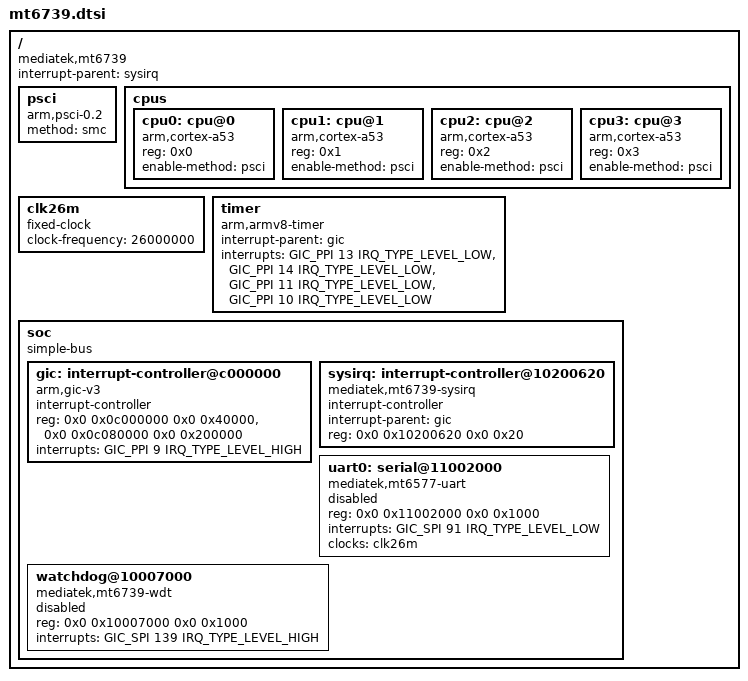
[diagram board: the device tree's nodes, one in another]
// SPDX-License-Identifier: GPL-2.0-only
/*
 * MediaTek MT6739 SoC
 *
 * Minimal mainline-shaped description: CPUs, PSCI, GICv3, arch timer, UART
 * and the top reset controller.  Clock, pinctrl, MMC and display nodes are
 * added as their drivers are ported.
 */

#include <dt-bindings/interrupt-controller/arm-gic.h>
#include <dt-bindings/interrupt-controller/irq.h>

/ {
	compatible = "mediatek,mt6739";
	interrupt-parent = <&sysirq>;
	#address-cells = <2>;
	#size-cells = <2>;

	psci {
		compatible = "arm,psci-0.2";
		method = "smc";
	};

	cpus {
		#address-cells = <1>;
		#size-cells = <0>;

		cpu0: cpu@0 {
			device_type = "cpu";
			compatible = "arm,cortex-a53";
			reg = <0x0>;
			enable-method = "psci";
		};

		cpu1: cpu@1 {
			device_type = "cpu";
			compatible = "arm,cortex-a53";
			reg = <0x1>;
			enable-method = "psci";
		};

		cpu2: cpu@2 {
			device_type = "cpu";
			compatible = "arm,cortex-a53";
			reg = <0x2>;
			enable-method = "psci";
		};

		cpu3: cpu@3 {
			device_type = "cpu";
			compatible = "arm,cortex-a53";
			reg = <0x3>;
			enable-method = "psci";
		};
	};

	clk26m: clk26m {
		compatible = "fixed-clock";
		#clock-cells = <0>;
		clock-frequency = <26000000>;
	};

	timer {
		compatible = "arm,armv8-timer";
		interrupt-parent = <&gic>;
		interrupts = <GIC_PPI 13 IRQ_TYPE_LEVEL_LOW>,
			     <GIC_PPI 14 IRQ_TYPE_LEVEL_LOW>,
			     <GIC_PPI 11 IRQ_TYPE_LEVEL_LOW>,
			     <GIC_PPI 10 IRQ_TYPE_LEVEL_LOW>;
	};

	soc {
		compatible = "simple-bus";
		#address-cells = <2>;
		#size-cells = <2>;
		ranges;

		gic: interrupt-controller@c000000 {
			compatible = "arm,gic-v3";
			#interrupt-cells = <3>;
			#address-cells = <2>;
			#size-cells = <2>;
			interrupt-controller;
			reg = <0x0 0x0c000000 0x0 0x40000>,	/* GICD */
			      <0x0 0x0c080000 0x0 0x200000>;	/* GICR */
			interrupts = <GIC_PPI 9 IRQ_TYPE_LEVEL_HIGH>;
		};

		sysirq: interrupt-controller@10200620 {
			compatible = "mediatek,mt6739-sysirq",
				     "mediatek,mt6577-sysirq";
			interrupt-controller;
			#interrupt-cells = <3>;
			interrupt-parent = <&gic>;
			reg = <0x0 0x10200620 0x0 0x20>;
		};

		uart0: serial@11002000 {
			compatible = "mediatek,mt6577-uart";
			reg = <0x0 0x11002000 0x0 0x1000>;
			interrupts = <GIC_SPI 91 IRQ_TYPE_LEVEL_LOW>;
			clocks = <&clk26m>;
			clock-names = "baud";
			status = "disabled";
		};

		watchdog@10007000 {
			compatible = "mediatek,mt6739-wdt",
				     "mediatek,mt6589-wdt";
			reg = <0x0 0x10007000 0x0 0x1000>;
			interrupts = <GIC_SPI 139 IRQ_TYPE_LEVEL_HIGH>;
			status = "disabled";
		};
	};
};
